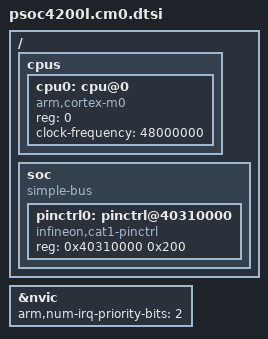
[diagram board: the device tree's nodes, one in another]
/*
 * Copyright (c) 2025 PSoC 4200L Zephyr Port
 * SPDX-License-Identifier: Apache-2.0
 */

#include <arm/armv6-m.dtsi>

/ {
	cpus {
		#address-cells = <1>;
		#size-cells = <0>;

		cpu0: cpu@0 {
			device_type = "cpu";
			compatible = "arm,cortex-m0";
			reg = <0>;
			clock-frequency = <48000000>;
		};
	};

	soc {
		compatible = "simple-bus";
		#address-cells = <1>;
		#size-cells = <1>;
		ranges;

		pinctrl0: pinctrl@40310000 {
			compatible = "infineon,cat1-pinctrl";
			reg = <0x40310000 0x200>;
		};
	};
};

&nvic {
	arm,num-irq-priority-bits = <2>;
};
